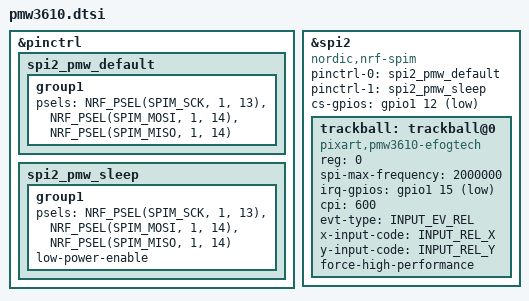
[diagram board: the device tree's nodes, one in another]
#include <zephyr/dt-bindings/input/input-event-codes.h>

&pinctrl {
    spi2_pmw_default: spi2_pmw_default {
        group1 {
            psels = <NRF_PSEL(SPIM_SCK,  1, 13)>,
                    <NRF_PSEL(SPIM_MOSI, 1, 14)>,
                    <NRF_PSEL(SPIM_MISO, 1, 14)>;
        };
    };
    spi2_pmw_sleep: spi2_pmw_sleep {
        group1 {
            psels = <NRF_PSEL(SPIM_SCK,  1, 13)>,
                    <NRF_PSEL(SPIM_MOSI, 1, 14)>,
                    <NRF_PSEL(SPIM_MISO, 1, 14)>;
            low-power-enable;
        };
    };
};

&spi2 {
    status = "okay";
    compatible = "nordic,nrf-spim";
    pinctrl-0 = <&spi2_pmw_default>;
    pinctrl-1 = <&spi2_pmw_sleep>;
    pinctrl-names = "default", "sleep";
    cs-gpios = <&gpio1 12 GPIO_ACTIVE_LOW>;

    trackball: trackball@0 {
        status = "okay";
        compatible = "pixart,pmw3610-efogtech";
        reg = <0>;
        spi-max-frequency = <2000000>;
        irq-gpios = <&gpio1 15 (GPIO_ACTIVE_LOW | GPIO_PULL_UP)>;
        cpi = <600>;
        evt-type = <INPUT_EV_REL>;
        x-input-code = <INPUT_REL_X>;
        y-input-code = <INPUT_REL_Y>;
        force-high-performance;
    };
};
